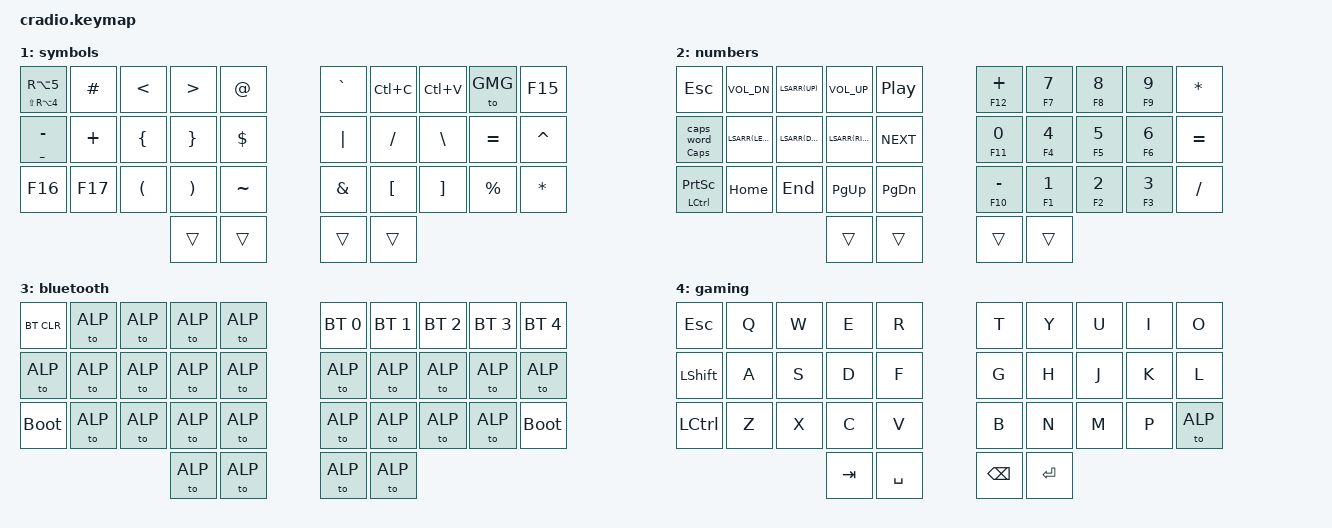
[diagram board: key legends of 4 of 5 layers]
// Copyright (c) 2022 The ZMK Contributors
// SPDX-License-Identifier: MIT

#include <behaviors.dtsi>
#include <dt-bindings/zmk/keys.h>
#include <dt-bindings/zmk/bt.h>

// Layer numbers definition
#define ALP 0
#define SYM 1
#define NUM 2
#define BLT 3
#define GMG 4

// Home row mods macro
#define HRML(k1,k2,k3,k4) &hm LGUI k1  &hm LALT k2  &hm LCTRL k3  &hm LSHIFT k4
#define HRMR(k1,k2,k3,k4) &hm RSHIFT k1  &hm RCTRL k2  &hm RALT k3  &hm LGUI k4

// Arrow key SHIFT mods macro
#define LSARR(k) &td LS(k) k

/ {
    combos {
        compatible = "zmk,combos";
        combo_blt {
            timeout-ms = <50>;
            key-positions = <16 17 18>;
            layers = <NUM>;
            bindings = <&to BLT>;
        };
        combo_mute {
            timeout-ms = <50>;
            key-positions = <1 3>;
            layers = <NUM>;
            bindings = <&kp C_MUTE>;
        };
        combo_prev {
            timeout-ms = <50>;
            key-positions = <4 14>;
            layers = <NUM>;
            bindings = <&kp C_PREV>;
        };
    };
    
    behaviors {
        hm: homerow_mod {
            label = "HOMEROW_MOD";
            compatible = "zmk,behavior-hold-tap";
            #binding-cells = <2>;
            flavor = "tap-preferred";
            tapping-term-ms = <300>;
            quick-tap-ms = <250>;
            bindings = <&kp>, <&kp>;
        };
        hl: homerow_layer {
			compatible = "zmk,behavior-hold-tap";
			label = "HOMEROW_LAYER";
			#binding-cells = <2>;
			tapping-term-ms = <220>;
			quick-tap-ms = <250>;
			flavor = "tap-preferred";
			bindings = <&mo>, <&kp>;
        };
    	td: tapdance {
			compatible = "zmk,behavior-hold-tap";
			label = "TAPDANCE";
			#binding-cells = <2>;
			tapping-term-ms = <190>;
			quick-tap-ms = <250>;
			flavor = "tap-preferred";
			bindings = <&kp>, <&kp>;
		};
        skm: sticky_key_modifier {
            label = "STICKY_KEY_MODIFIER";
            compatible = "zmk,behavior-sticky-key";
            #binding-cells = <1>;
            release-after-ms = <1000>;
            quick-release;
            ignore-modifiers;
            bindings = <&kp>;
        };
        caps: caps_word_lock {
			compatible = "zmk,behavior-hold-tap";
			label = "CAPS_WORD_LOCK";
			#binding-cells = <2>;
			tapping-term-ms = <190>;
			quick-tap-ms = <250>;
			flavor = "tap-preferred";
			bindings = <&kp>, <&caps_word>;
		};
    };

    keymap {
        compatible = "zmk,keymap";
        default_layer {
            bindings = <
        //╭──────────────┬──────────────┬──────────────┬──────────────┬──────────────╮   ╭──────────────┬──────────────┬──────────────┬──────────────┬──────────────╮
        //│  Q Å         │  W           │  F           │  P           │  B           │   │  J           │  L           │  U Æ         │  Y Ø         │  ? !         │
            &td RA(W) Q    &kp W          &kp F          &kp P          &kp B              &kp J          &kp L          &td RA(Z) U    &td RA(L) Y    &td EXCL QMARK
        //├──────────────┼──────────────┼──────────────┼──────────────┼──────────────┤   ├──────────────┼──────────────┼──────────────┼──────────────┼──────────────┤
        //│  A LGUI      │  R LALT      │  S LCTRL     │  T LSHIFT    │  G           │   │  M           │  N RSHIFT    │  E RCTRL     │  I RALT      │  O RGUI      │
            HRML(A,        R,             S,             T)             &kp G              &kp M          HRMR(N,        E,             I,             O)
        //├──────────────┼──────────────┼──────────────┼──────────────┼──────────────┤   ├──────────────┼──────────────┼──────────────┼──────────────┼──────────────┤
        //│  Z           │  X           │  C           │  D           │  V           │   │  K           │  H           │  , ;         │  . :         │  ' "         │
            &kp Z          &kp X          &kp C          &kp D          &kp V              &kp K          &kp H         &td SEMI COMMA  &td COLON DOT  &td DQT SQT
        //╰──────────────┴──────────────┴──────────────┼──────────────┼──────────────┤   ├──────────────┼──────────────┼──────────────┴──────────────┴──────────────╯
        //                                             │  TAB NUM     │  SPACE MEH   │   │  BSPC +CTRL  │  SYM ENTER   │
                                                    &hl NUM TAB  &hm LC(LS(LALT)) SPACE  &td RC(BSPC) BSPC  &hl SYM ENTER
        //                                             ╰──────────────┴──────────────╯   ╰──────────────┴──────────────╯
            >;
        };

        symbols {
            bindings = <
        //╭──────────────┬──────────────┬──────────────┬──────────────┬──────────────╮   ╭──────────────┬──────────────┬──────────────┬──────────────┬──────────────╮
        //│  € £         │  #           │  <           │  >           │  @           │   │  GRAVE       │  COPY        │  PASTE       │  GMG         │  GRAVE       │
            &td LS(RA(N4)) RA(N5)  &kp HASH  &kp LT      &kp GT         &kp AT             &kp GRAVE      &kp LC(C)      &kp LC(V)      &to GMG        &kp F15
        //├──────────────┼──────────────┼──────────────┼──────────────┼──────────────┤   ├──────────────┼──────────────┼──────────────┼──────────────┼──────────────┤
        //│  - _         │  +           │  {           │  }           │  $           │   │  |           │  /           │  \           │  =           │  ^           │
            &td UNDER MINUS  &kp PLUS     &kp LBRC       &kp RBRC       &kp DLLR           &kp PIPE       &kp FSLH       &kp BSLH       &kp EQUAL      &kp CARET
        //├──────────────┼──────────────┼──────────────┼──────────────┼──────────────┤   ├──────────────┼──────────────┼──────────────┼──────────────┼──────────────┤
        //│  F16         │  F17         │  (           │  )           │  ~           │   │  &           │  [           │  ]           │  %           │  *           │
            &kp F16        &kp F17        &kp LPAR       &kp RPAR       &kp TILDE          &kp AMPS       &kp LBKT       &kp RBKT       &kp PRCNT      &kp STAR
        //╰──────────────┴──────────────┴──────────────┼──────────────┼──────────────┤   ├──────────────┼──────────────┼──────────────┴──────────────┴──────────────╯
        //                                             │              │              │   │              │              │
                                                         &trans          &trans            &trans         &trans
        //                                             ╰──────────────┴──────────────╯   ╰──────────────┴──────────────╯
            >;
        };

        numbers {
            bindings = <
        //╭──────────────┬──────────────┬──────────────┬──────────────┬──────────────╮   ╭──────────────┬──────────────┬──────────────┬──────────────┬──────────────╮ 
        //│  ESC         │  VOL DOWN    │  UP +LS      │  VOL UP      │  MED PAUSE   │   │  + F12       │  7 F7        │  8 F8        │  9 F9        │  *           │ VOL DOWN + VOL UP = MUTE
            &kp ESC        &kp C_VOL_DN   LSARR(UP)      &kp C_VOL_UP   &kp C_PP           &td F12 PLUS   &td F7 N7      &td F8 N8      &td F9 N9      &kp STAR
        //├──────────────┼──────────────┼──────────────┼──────────────┼──────────────┤   ├──────────────┼──────────────┼──────────────┼──────────────┼──────────────┤ 4 + 5 + 6 = BLT
        //│  CAPS WL     │  LEFT +LS    │  DOWN +LS    │  RIGHT +LS   │  MED NEXT    │   │  0 F11       │  4 F4        │  5 F5        │  6 F6        │  =           │ MED PAUSE + MED FWD = BACK
            &caps CAPS 0   LSARR(LEFT)    LSARR(DOWN)    LSARR(RIGHT)   &kp C_NEXT         &td F11 N0     &td F4 N4      &td F5 N5      &td F6 N6      &kp EQUAL
        //├──────────────┼──────────────┼──────────────┼──────────────┼──────────────┤   ├──────────────┼──────────────┼──────────────┼──────────────┼──────────────┤
        //│  PSCRN LCTRL │  HOME        │  END         │  PAGE UP     │  PAGE DOWN   │   │  - F10       │  1 F1        │  2 F2        │  3 F3        │  /           │
            &hm LCTRL PSCRN  &kp HOME     &kp END        &kp PG_UP      &kp PG_DN          &td F10 MINUS  &td F1 N1      &td F2 N2      &td F3 N3      &kp FSLH
        //╰──────────────┴──────────────┴──────────────┼──────────────┼──────────────┤   ├──────────────┼──────────────┼──────────────┴──────────────┴──────────────╯
        //                                             │              │              │   │              │              │
                                                         &trans         &trans             &trans         &trans
        //                                             ╰──────────────┴──────────────╯   ╰──────────────┴──────────────╯
            >;
        };

        bluetooth {
            bindings = <
        //╭──────────────┬──────────────┬──────────────┬──────────────┬──────────────╮   ╭──────────────┬──────────────┬──────────────┬──────────────┬──────────────╮
        //│              │              │              │              │              │   │              │              │              │              │              │
            &bt BT_CLR     &to ALP        &to ALP        &to ALP        &to ALP            &bt BT_SEL 0   &bt BT_SEL 1   &bt BT_SEL 2   &bt BT_SEL 3   &bt BT_SEL 4
        //├──────────────┼──────────────┼──────────────┼──────────────┼──────────────┤   ├──────────────┼──────────────┼──────────────┼──────────────┼──────────────┤
        //│              │              │              │              │              │   │              │              │              │              │              │
            &to ALP        &to ALP        &to ALP        &to ALP        &to ALP            &to ALP        &to ALP        &to ALP        &to ALP        &to ALP
        //├──────────────┼──────────────┼──────────────┼──────────────┼──────────────┤   ├──────────────┼──────────────┼──────────────┼──────────────┼──────────────┤
        //│              │              │              │              │              │   │              │              │              │              │              │
            &bootloader    &to ALP        &to ALP        &to ALP        &to ALP            &to ALP        &to ALP        &to ALP        &to ALP        &bootloader
        //╰──────────────┴──────────────┴──────────────┼──────────────┼──────────────┤   ├──────────────┼──────────────┼──────────────┴──────────────┴──────────────╯
        //                                             │              │              │   │              │              │
                                                         &to ALP        &to ALP            &to ALP        &to ALP        
        //                                             ╰──────────────┴──────────────╯   ╰──────────────┴──────────────╯
            >;
        };

        gaming {
            bindings = <
        //╭──────────────┬──────────────┬──────────────┬──────────────┬──────────────╮   ╭──────────────┬──────────────┬──────────────┬──────────────┬──────────────╮
        //│  ESC         │  Q           │  W           │  E           │  R           │   │  T           │  Y           │  U           │  I           │  O           │
            &kp ESC        &kp Q          &kp W          &kp E          &kp R              &kp T          &kp Y          &kp U          &kp I          &kp O
        //├──────────────┼──────────────┼──────────────┼──────────────┼──────────────┤   ├──────────────┼──────────────┼──────────────┼──────────────┼──────────────┤
        //│  LSHFT       │  A           │  S           │  D           │  F           │   │  G           │  H           │  J           │  K           │  L           │
            &kp LSHFT      &kp A          &kp S          &kp D          &kp F              &kp G          &kp H          &kp J          &kp K          &kp L
        //├──────────────┼──────────────┼──────────────┼──────────────┼──────────────┤   ├──────────────┼──────────────┼──────────────┼──────────────┼──────────────┤
        //│  LCTRL       │  Z           │  X           │  C           │  V           │   │  B           │  N           │  M           │  P           │  ALP         │
            &kp LCTRL      &kp Z          &kp X          &kp C          &kp V              &kp B          &kp N          &kp M          &kp P          &to ALP
        //╰──────────────┴──────────────┴──────────────┼──────────────┼──────────────┤   ├──────────────┼──────────────┼──────────────┴──────────────┴──────────────╯
        //                                             │  TAB         │  SPACE       │   │  BSPC        │  ENTER       │
                                                         &kp TAB        &kp SPACE          &kp BSPC       &kp ENTER        
        //                                             ╰──────────────┴──────────────╯   ╰──────────────┴──────────────╯
            >;
        };
    };
};
